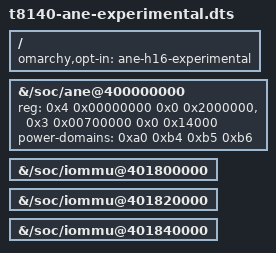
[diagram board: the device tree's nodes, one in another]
// SPDX-License-Identifier: GPL-2.0-only OR MIT
/*
 * ane/h16 OPT-IN EXPERIMENTAL overlay for T8140 (J700 / A18 Pro-class)
 * board device trees, for ane_h16 (apple,t8140-ane). NOT INSTALLED by the
 * package. The first owner compiles it and copies it into the overlay
 * directory by hand, with the opt-in key ane-h16-experimental in
 * /etc/omarchy-mac-boot/dtb-overlays.opt-in. See ane/h16/README-bringup.
 *
 * Unlike the T8132 template, the aurora T8140 tree already contains the
 * ane@400000000 node (disabled) and the three iommu@4018x0000 DART nodes
 * (disabled, compatible "apple,t8140-dart", "apple,t8110-dart"). This
 * overlay only:
 *   1. gives the ANE node the second "pmgr" reg window the driver maps by
 *      name, plus the full power-domain set (ANE_SYS + the three CPU-island
 *      words), and marks it okay;
 *   2. marks the three DARTs okay.
 *
 * Phandles are literal (verified against the running T8140 tree):
 *   0xa0 = power-management@300700000/power-controller@290  (ANE_SYS)
 *   0xb4 = .../power-controller@c000  (ANE_CPU island)
 *   0xb5 = .../power-controller@c008
 *   0xb6 = .../power-controller@c010
 * They are fixed in this tree; re-verify before applying on a different
 * board.
 */
/dts-v1/;
/plugin/;

/ {
	omarchy,opt-in = "ane-h16-experimental";

	fragment@0 {
		target-path = "/soc/ane@400000000";
		__overlay__ {
			reg-names = "engine", "pmgr";
			reg = <0x4 0x00000000 0x0 0x2000000>,
			      <0x3 0x00700000 0x0 0x14000>;
			power-domains = <0xa0 0xb4 0xb5 0xb6>;
			status = "okay";
		};
	};

	fragment@1 {
		target-path = "/soc/iommu@401800000";
		__overlay__ {
			status = "okay";
		};
	};

	fragment@2 {
		target-path = "/soc/iommu@401820000";
		__overlay__ {
			status = "okay";
		};
	};

	fragment@3 {
		target-path = "/soc/iommu@401840000";
		__overlay__ {
			status = "okay";
		};
	};
};
